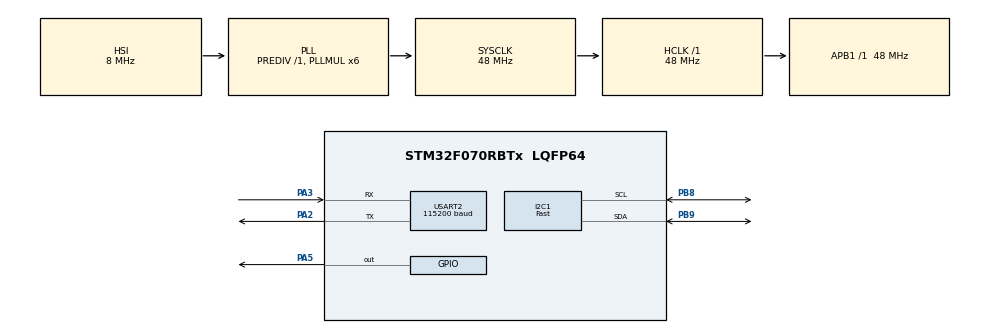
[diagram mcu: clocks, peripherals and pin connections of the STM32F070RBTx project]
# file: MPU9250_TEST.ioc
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FREERTOS.Tasks01=defaultTask,0,128,StartDefaultTask,Default,NULL
FREERTOS.configTOTAL_HEAP_SIZE=4096
I2C1.I2C_Coeff_DF=5
I2C1.I2C_Fall_Time=300
I2C1.I2C_Rise_Time=300
I2C1.I2C_Speed_Mode=I2C_Fast
I2C1.Timing=0x00300003
Mcu.Family=STM32F0
Mcu.Name=STM32F070RBTx
Mcu.Package=LQFP64
NVIC.TIM15_IRQn=true\:3\:0\:false\:false\:true\:true\:true
NVIC.TIM3_IRQn=true\:3\:0\:false\:false\:true\:true\:true
NVIC.USART2_IRQn=true\:3\:0\:false\:false\:true\:true\:true
PA13.Mode=Serial_Wire
PA13.Signal=SYS_SWDIO
PA14.Mode=Serial_Wire
PA14.Signal=SYS_SWCLK
PA2.Mode=Asynchronous
PA2.Signal=USART2_TX
PA3.Mode=Asynchronous
PA3.Signal=USART2_RX
PA5.GPIO_Speed=GPIO_SPEED_FREQ_HIGH
PA5.Signal=GPIO_Output
PB8.Mode=I2C
PB8.Signal=I2C1_SCL
PB9.Mode=I2C
PB9.Signal=I2C1_SDA
PC14-OSC32_IN.Mode=LSE-External-Oscillator
PC14-OSC32_IN.Signal=RCC_OSC32_IN
PC15-OSC32_OUT.Mode=LSE-External-Oscillator
PC15-OSC32_OUT.Signal=RCC_OSC32_OUT
ProjectManager.HeapSize=0x200
ProjectManager.StackSize=0x400
ProjectManager.TargetToolchain=MDK-ARM V5
RCC.AHBFreq_Value=48000000
RCC.APB1Freq_Value=48000000
RCC.APB1TimFreq_Value=48000000
RCC.HCLKFreq_Value=48000000
RCC.PLLMUL=RCC_PLL_MUL6
RCC.SYSCLKFreq_VALUE=48000000
RCC.SYSCLKSource=RCC_SYSCLKSOURCE_PLLCLK
TIM15.Period=9999
TIM15.Prescaler=23
TIM3.Period=99
TIM3.Prescaler=47
USART2.BaudRate=115200
USART2.VirtualMode-Asynchronous=VM_ASYNC
USART2.WordLength=WORDLENGTH_8B
VP_FREERTOS_VS_ENABLE.Mode=Enabled
VP_TIM15_VS_ClockSourceINT.Mode=Internal
VP_TIM3_VS_ClockSourceINT.Mode=Internal
board=MPU9250_TEST

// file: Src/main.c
/**
  ******************************************************************************
  * @file           : main.c
  * @brief          : Main program body
  ******************************************************************************
  * This notice applies to any and all portions of this file
  * that are not between comment pairs USER CODE BEGIN and
  * USER CODE END. Other portions of this file, whether
  * inserted by the user or by software development tools
  * are owned by their respective copyright owners.
  *
  * Copyright (c) 2018 STMicroelectronics International N.V.
  * All rights reserved.
  *
  * Redistribution and use in source and binary forms, with or without
  * modification, are permitted, provided that the following conditions are met:
  *
  * 1. Redistribution of source code must retain the above copyright notice,
  *    this list of conditions and the following disclaimer.
  * 2. Redistributions in binary form must reproduce the above copyright notice,
  *    this list of conditions and the following disclaimer in the documentation
  *    and/or other materials provided with the distribution.
  * 3. Neither the name of STMicroelectronics nor the names of other
  *    contributors to this software may be used to endorse or promote products
  *    derived from this software without specific written permission.
  * 4. This software, including modifications and/or derivative works of this
  *    software, must execute solely and exclusively on microcontroller or
  *    microprocessor devices manufactured by or for STMicroelectronics.
  * 5. Redistribution and use of this software other than as permitted under
  *    this license is void and will automatically terminate your rights under
  *    this license.
  *
  * THIS SOFTWARE IS PROVIDED BY STMICROELECTRONICS AND CONTRIBUTORS "AS IS"
  * AND ANY EXPRESS, IMPLIED OR STATUTORY WARRANTIES, INCLUDING, BUT NOT
  * LIMITED TO, THE IMPLIED WARRANTIES OF MERCHANTABILITY, FITNESS FOR A
  * PARTICULAR PURPOSE AND NON-INFRINGEMENT OF THIRD PARTY INTELLECTUAL PROPERTY
  * RIGHTS ARE DISCLAIMED TO THE FULLEST EXTENT PERMITTED BY LAW. IN NO EVENT
  * SHALL STMICROELECTRONICS OR CONTRIBUTORS BE LIABLE FOR ANY DIRECT, INDIRECT,
  * INCIDENTAL, SPECIAL, EXEMPLARY, OR CONSEQUENTIAL DAMAGES (INCLUDING, BUT NOT
  * LIMITED TO, PROCUREMENT OF SUBSTITUTE GOODS OR SERVICES; LOSS OF USE, DATA,
  * OR PROFITS; OR BUSINESS INTERRUPTION) HOWEVER CAUSED AND ON ANY THEORY OF
  * LIABILITY, WHETHER IN CONTRACT, STRICT LIABILITY, OR TORT (INCLUDING
  * NEGLIGENCE OR OTHERWISE) ARISING IN ANY WAY OUT OF THE USE OF THIS SOFTWARE,
  * EVEN IF ADVISED OF THE POSSIBILITY OF SUCH DAMAGE.
  *
  ******************************************************************************
  */
#include "main.h"
#include "stm32f0xx_hal.h"
#include "cmsis_os.h"
#include "i2c.h"
#include "tim.h"
#include "usart.h"
#include "gpio.h"

/* USER CODE BEGIN PV */
/* Private variables ---------------------------------------------------------*/

/* USER CODE END PV */

void SystemClock_Config(void);
void MX_FREERTOS_Init(void);

/* USER CODE BEGIN PFP */
/* Private function prototypes -----------------------------------------------*/

/* USER CODE END PFP */

int main(void)
{

  /* MCU Configuration----------------------------------------------------------*/

  /* Reset of all peripherals, Initializes the Flash interface and the Systick. */
  HAL_Init();

  /* Configure the system clock */
  SystemClock_Config();

  /* Initialize all configured peripherals */
  MX_GPIO_Init();
  MX_I2C1_Init();
  MX_TIM3_Init();
  MX_TIM15_Init();
  MX_USART2_UART_Init();

  /* Call init function for freertos objects (in freertos.c) */
  MX_FREERTOS_Init();

  /* Start scheduler */
  osKernelStart();

  /* We should never get here as control is now taken by the scheduler */

  /* Infinite loop */
  while (1)
  {

  }

}

void SystemClock_Config(void)
{

  RCC_OscInitTypeDef RCC_OscInitStruct;
  RCC_ClkInitTypeDef RCC_ClkInitStruct;
  RCC_PeriphCLKInitTypeDef PeriphClkInit;

    /**Initializes the CPU, AHB and APB busses clocks
    */
  RCC_OscInitStruct.OscillatorType = RCC_OSCILLATORTYPE_HSI;
  RCC_OscInitStruct.HSIState = RCC_HSI_ON;
  RCC_OscInitStruct.HSICalibrationValue = 16;
  RCC_OscInitStruct.PLL.PLLState = RCC_PLL_ON;
  RCC_OscInitStruct.PLL.PLLSource = RCC_PLLSOURCE_HSI;
  RCC_OscInitStruct.PLL.PLLMUL = RCC_PLL_MUL6;
  RCC_OscInitStruct.PLL.PREDIV = RCC_PREDIV_DIV1;
  if (HAL_RCC_OscConfig(&RCC_OscInitStruct) != HAL_OK)
  {
    _Error_Handler(__FILE__, __LINE__);
  }

    /**Initializes the CPU, AHB and APB busses clocks
    */
  RCC_ClkInitStruct.ClockType = RCC_CLOCKTYPE_HCLK|RCC_CLOCKTYPE_SYSCLK
                              |RCC_CLOCKTYPE_PCLK1;
  RCC_ClkInitStruct.SYSCLKSource = RCC_SYSCLKSOURCE_PLLCLK;
  RCC_ClkInitStruct.AHBCLKDivider = RCC_SYSCLK_DIV1;
  RCC_ClkInitStruct.APB1CLKDivider = RCC_HCLK_DIV1;

  if (HAL_RCC_ClockConfig(&RCC_ClkInitStruct, FLASH_LATENCY_1) != HAL_OK)
  {
    _Error_Handler(__FILE__, __LINE__);
  }

  PeriphClkInit.PeriphClockSelection = RCC_PERIPHCLK_I2C1;
  PeriphClkInit.I2c1ClockSelection = RCC_I2C1CLKSOURCE_HSI;
  if (HAL_RCCEx_PeriphCLKConfig(&PeriphClkInit) != HAL_OK)
  {
    _Error_Handler(__FILE__, __LINE__);
  }

    /**Configure the Systick interrupt time
    */
  HAL_SYSTICK_Config(HAL_RCC_GetHCLKFreq()/1000);

    /**Configure the Systick
    */
  HAL_SYSTICK_CLKSourceConfig(SYSTICK_CLKSOURCE_HCLK);

  /* SysTick_IRQn interrupt configuration */
  HAL_NVIC_SetPriority(SysTick_IRQn, 3, 0);
}

void _Error_Handler(char *file, int line)
{
  while(1)
  {
  }
}

/************************ (C) COPYRIGHT STMicroelectronics *****END OF FILE****/

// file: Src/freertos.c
/**
  ******************************************************************************
  * File Name          : freertos.c
  * Description        : Code for freertos applications
  ******************************************************************************
  * This notice applies to any and all portions of this file
  * that are not between comment pairs USER CODE BEGIN and
  * USER CODE END. Other portions of this file, whether
  * inserted by the user or by software development tools
  * are owned by their respective copyright owners.
  *
  * Copyright (c) 2018 STMicroelectronics International N.V.
  * All rights reserved.
  *
  * Redistribution and use in source and binary forms, with or without
  * modification, are permitted, provided that the following conditions are met:
  *
  * 1. Redistribution of source code must retain the above copyright notice,
  *    this list of conditions and the following disclaimer.
  * 2. Redistributions in binary form must reproduce the above copyright notice,
  *    this list of conditions and the following disclaimer in the documentation
  *    and/or other materials provided with the distribution.
  * 3. Neither the name of STMicroelectronics nor the names of other
  *    contributors to this software may be used to endorse or promote products
  *    derived from this software without specific written permission.
  * 4. This software, including modifications and/or derivative works of this
  *    software, must execute solely and exclusively on microcontroller or
  *    microprocessor devices manufactured by or for STMicroelectronics.
  * 5. Redistribution and use of this software other than as permitted under
  *    this license is void and will automatically terminate your rights under
  *    this license.
  *
  * THIS SOFTWARE IS PROVIDED BY STMICROELECTRONICS AND CONTRIBUTORS "AS IS"
  * AND ANY EXPRESS, IMPLIED OR STATUTORY WARRANTIES, INCLUDING, BUT NOT
  * LIMITED TO, THE IMPLIED WARRANTIES OF MERCHANTABILITY, FITNESS FOR A
  * PARTICULAR PURPOSE AND NON-INFRINGEMENT OF THIRD PARTY INTELLECTUAL PROPERTY
  * RIGHTS ARE DISCLAIMED TO THE FULLEST EXTENT PERMITTED BY LAW. IN NO EVENT
  * SHALL STMICROELECTRONICS OR CONTRIBUTORS BE LIABLE FOR ANY DIRECT, INDIRECT,
  * INCIDENTAL, SPECIAL, EXEMPLARY, OR CONSEQUENTIAL DAMAGES (INCLUDING, BUT NOT
  * LIMITED TO, PROCUREMENT OF SUBSTITUTE GOODS OR SERVICES; LOSS OF USE, DATA,
  * OR PROFITS; OR BUSINESS INTERRUPTION) HOWEVER CAUSED AND ON ANY THEORY OF
  * LIABILITY, WHETHER IN CONTRACT, STRICT LIABILITY, OR TORT (INCLUDING
  * NEGLIGENCE OR OTHERWISE) ARISING IN ANY WAY OUT OF THE USE OF THIS SOFTWARE,
  * EVEN IF ADVISED OF THE POSSIBILITY OF SUCH DAMAGE.
  *
  ******************************************************************************
  */

#include "FreeRTOS.h"
#include "task.h"
#include "cmsis_os.h"

/* USER CODE BEGIN Includes */
#include "mpu9250.h"
/* USER CODE END Includes */

osThreadId defaultTaskHandle;

void StartDefaultTask(void const * argument);

void MX_FREERTOS_Init(void); /* (MISRA C 2004 rule 8.1) */

/* Hook prototypes */

/* Init FreeRTOS */

void MX_FREERTOS_Init(void) {
  /* USER CODE BEGIN Init */
       MPU9250_Init();
  /* USER CODE END Init */

  /* Create the thread(s) */
  /* definition and creation of defaultTask */
  osThreadDef(defaultTask, StartDefaultTask, osPriorityNormal, 0, 128);
  defaultTaskHandle = osThreadCreate(osThread(defaultTask), NULL);

}

/* StartDefaultTask function */
void StartDefaultTask(void const * argument)
{

  for(;;)
  {
    osDelay(1);
  }
}

/************************ (C) COPYRIGHT STMicroelectronics *****END OF FILE****/
